# haltium_application register map
Vendor: Nordic Semiconductor; Series: nRFHaltium; File version: 1
CPU: CM33 r0p4, little endian, MPU, FPU, 3 interrupt priority bits, 480 interrupts
Registers are 32-bit, read-write, reset 0x0 unless marked. A register's access mark holds for its fields unless they carry their own. Offsets are from the block's base; [hi:lo] are bit positions; lines under a group give offsets from that group; {n}, {i} and the like mark numbered series; 'fields as' and 'values as' point back to an identical list.

## BICR_NS — Board information configuration registers
Base 0x0FFF87B0; alternate view of UICR_NS
0x00 POWER group — Unspecified
  0x00 CONFIG reset 0xFFFFFFFF — Power configuration of power rails.
    [31] INDUCTOR — DC/DC inductor presence.
      1=NotPresent (DC/DC inductor is not present.); 0=Present (DC/DC inductor is present.)
    [23:20] VDDDSI1V8 — VDD_DSI_1V8 power configuration.
      15=Unconfigured (Power rail is unconfigured.); 1=External (Power rail is configured to be externally powered.); 2=Shorted (Power rail is shorted to VDD_AO_1V8.); 3=Grounded (Power rail is grounded. DSI shall not be used.)
    [19:16] VDDVS0V8 — VDD_VS_0V8 power configuration.
      15=Unconfigured (Power rail is unconfigured.); 0=Internal (Power rail is configured to use the internal regulator.); 1=External (Power rail is configured to be externally powered.)
    [15:12] VDDAO0V8 — VDD_AO_0V8 power configuration.
      values as VDDVS0V8
    [11:8] VDDRF1V0 — VDD_RF_1V0 power configuration.
      15=Unconfigured (Power rail is unconfigured.); 1=External (Power rail is configured to be externally powered.); 2=Shorted (Power rail is shorted to VDD_1V0.)
    [7:4] VDD1V0 — VDD_1V0 power configuration.
      values as VDDVS0V8
    [3:0] VDDAO1V8 — VDD_AO_1V8 power configuration.
      values as VDDVS0V8
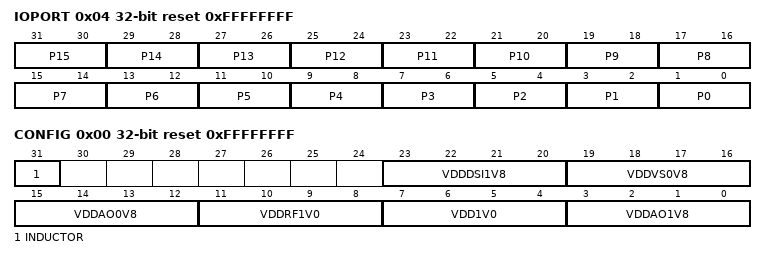
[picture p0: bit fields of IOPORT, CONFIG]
  0x04 IOPORT reset 0xFFFFFFFF — Power configuration of IO ports.
    [all] fields
      3=Unconfigured (Port supply is unconfigured.); 0=Disconnected (Port supply rail is not connected. Port cannot be used.); 1=External (Port supply is provided externally.); 2=Shorted (Port supply is shorted to VDD_AO_1V8.)
    [2n+1:2n] P{n} (n=0..15) — P{n} power configuration.
  {0x8+4j} MISPROT[{j}] (j=0..1) reset 0xFFFFFFFF — Description collection: Misconfiguration protection for power configuration. Whenever chaning any register in the POWER group, these registers MUST be written to 0xFFFFFFFF to indicate the system to perform the misconfiguration protection sequence.
    [31:0] MISPROT
      0xFFFFFFFF=Modified (Power configuration has been modified.)
0x14 LFXO group — Unspecified
  0x00 CONFIG reset 0xFFFFFFFF — LFXO configuration.
    [19:12] LOADCAP — Built-in load capacitors selection in 1 pF steps. Max. value 25 pF.
      255=Unconfigured (The built-in load capacitors is unconfigured. LFXO will not start unless LOADCAP is configured.); 0=External (Do not use the built-in load capacitors, only external capacitors will be used.)
    [10:8] MODE — LFXO mode.
      7=Unconfigured (The mode is unconfigured.); 0=Pierce (LFXO Pierce mode.); 1=PIXO (LFXO PIXO mode.); 2=ExtSine (LFXO in external sine wave mode.); 3=ExtSquare (LFXO in external square wave mode.)
    [7:4] ACCURACY — LFXO crystal or external signal accuracy.
      15=Unconfigured (The accuracy is unconfigured.); 0=500ppm (LFXO crystal or external signal has an accuracy of 500 ppm.); 1=250ppm (LFXO crystal or external signal has an accuracy of 250 ppm.); 2=150ppm (LFXO crystal or external signal has an accuracy of 150 ppm.); 3=100ppm (LFXO crystal or external signal has an accuracy of 100 ppm.); 4=75ppm (LFXO crystal or external signal has an accuracy of 75 ppm.); 5=50ppm (LFXO crystal or external signal has an accuracy of 50 ppm.); 6=30ppm (LFXO crystal or external signal has an accuracy of 30 ppm.); 7=20ppm (LFXO crystal or external signal has an accuracy of 20 ppm.)
    [0] PRESENCE — LFXO crystal or external signal presence.
      1=NotPresent (LFXO crystal or external signal is not present.); 0=Present (LFXO crystal or external signal is present.)
  0x04 CALIBRATION reset 0xFFFFFFFF — LFXO calibration needed. Must be written to 0xFFFFFFFF after any modification of the LFXO board circuit, load capacitance, or crystal swap.
    [31:0] CALIBRATION
      0xFFFFFFFF=Calibrate the LFXO at startup
  0x08 STARTUPTIME reset 0xFFFFFFFF — LFXO startup time in us.
    [31:0] TIME
      0xFFFFFFFF=Unconfigured (Startup time has not been configured.)
0x24 HFXO group — Unspecified
  0x00 CONFIG reset 0xFFFFFFFF — HFXO configuration.
    [19:12] LOADCAP — Built-in load capacitors selection in 1 pF steps. Max. value 25 pF.
      255=Unconfigured (The built-in load capacitors is unconfigured. HFXO will not start unless LOADCAP is configured.); 0=External (Do not use the built-in load capacitors, only external capacitors will be used.)
    [10:8] MODE — HFXO mode.
      7=Unconfigured (The mode is unconfigured.); 0=Pierce (HFXO Pierce mode.); 1=PIXO (HFXO PIXO mode.); 3=ExtSquare (HFXO in external square wave mode.); 6=Auto (Either Pierce or PIXO automatically handled by the system based on system requests.)
  0x04 STARTUPTIME reset 0xFFFFFFFF — HFXO startup time in us.
    fields as LFXO.STARTUPTIME
